# STM32C011D6Y6 register map
File version: 1.0
STM32C011D6Y6,STM32C011F4P6,STM32C011F4U6,STM32C011F6P6,STM32C011F6U6,STM32C011J4M6,STM32C011J6M6,STM32C031C4T6,STM32C031C4U6,STM32C031C6T6,STM32C031C6U6,STM32C031F4P6,STM32C031F6P6,STM32C031G4U6,STM32C031G6U6,STM32C031K4T6,STM32C031K4U6,STM32C031K6T6,STM32C031K6U6
Registers are 32-bit, access not given, reset 0x0 unless marked. A register's access mark holds for its fields unless they carry their own. Offsets are from the block's base; lines under a group give offsets from that group; [hi:lo] are bit positions; {n}, {i} and the like mark numbered series; 'fields as' and 'values as' point back to an identical list; <NAME> marks a mode.

## Memory map
0x40000400 TIM3
0x40002000 TIM14
0x40002800 RTC
0x40002C00 WWDG
0x40003000 IWDG
0x40004400 USART2
0x40005400 I2C1
0x40007000 PWR
0x40010000 SYSCFG
0x40010080 ITLINE
0x40012400 ADC
0x40012C00 TIM1
0x40013000 SPI1
0x40013800 USART1
0x40014400 TIM16
0x40014800 TIM17
0x40015800 DBG
0x40020000 DMA1
0x40020800 DMAMUX
0x40021000 RCC
0x40021800 EXTI
0x40022000 FLASH
0x40023000 CRC
0x50000000 GPIOA
0x50000400 GPIOB
0x50000800 GPIOC
0x50000C00 GPIOD
0x50001400 GPIOF

## TIM3
Base 0x40000400
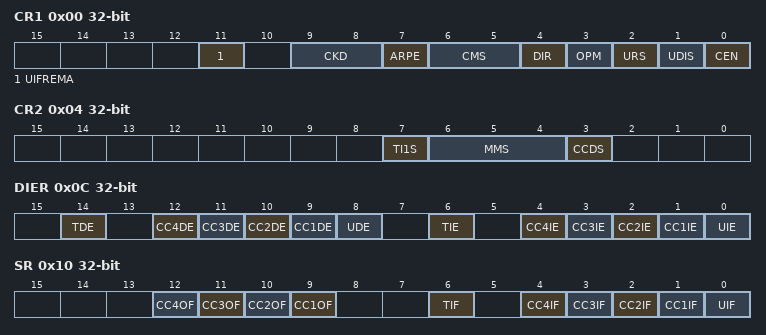
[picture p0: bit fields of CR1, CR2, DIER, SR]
0x00 CR1
  [11] UIFREMA, [9:8] CKD, [7] ARPE, [6:5] CMS, [4] DIR, [3] OPM, [2] URS, [1] UDIS, [0] CEN
0x04 CR2
  [7] TI1S, [6:4] MMS, [3] CCDS
0x08 SMCR
  [15] ETP, [14] ECE, [13:12] ETPS, [11:8] ETF, [7] MSM, [21:4] TS, [16:0] SMS
0x0C DIER
  [14] TDE, [n+8] CC{n}DE (n=1..4), [8] UDE, [6] TIE, [n] CC{n}IE (n=1..4), [0] UIE
0x10 SR
  [n+8] CC{n}OF (n=1..4), [6] TIF, [n] CC{n}IF (n=1..4), [0] UIF
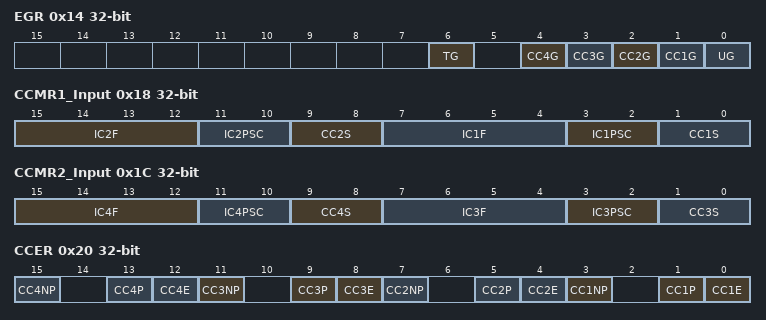
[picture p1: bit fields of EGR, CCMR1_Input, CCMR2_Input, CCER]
0x14 EGR
  [6] TG, [n] CC{n}G (n=1..4), [0] UG
0x18 CCMR1_Output
  [15] OC2CE, [24:12] OC2M, [11] OC2PE, [10] OC2FE, [9:8] CC2S, [7] OC1CE, [16:4] OC1M, [3] OC1PE, [2] OC1FE, [1:0] CC1S
0x18 CCMR1_Input
  [15:12] IC2F, [11:10] IC2PSC, [9:8] CC2S, [7:4] IC1F, [3:2] IC1PSC, [1:0] CC1S
0x1C CCMR2_Output
  [15] O24CE, [24:12] OC4M, [11] OC4PE, [10] OC4FE, [9:8] CC4S, [7] OC3CE, [16:4] OC3M, [3] OC3PE, [2] OC3FE, [1:0] CC3S
0x1C CCMR2_Input
  [15:12] IC4F, [11:10] IC4PSC, [9:8] CC4S, [7:4] IC3F, [3:2] IC3PSC, [1:0] CC3S
0x20 CCER
  [4n-1] CC{n}NP (n=1..4), [4n-3] CC{n}P (n=1..4), [4n-4] CC{n}E (n=1..4)
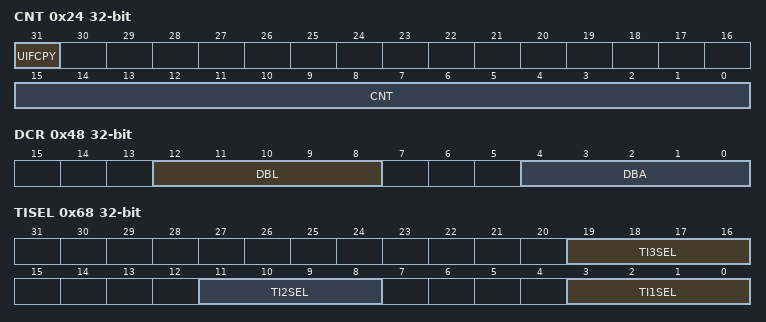
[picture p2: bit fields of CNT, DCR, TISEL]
0x24 CNT
  [31] UIFCPY, [15:0] CNT
0x28 PSC
  [15:0] PSC
0x2C ARR
  [15:0] ARR
{0x30+4i} CCR{i} (i=1..4)
  [15:0] CCR{i}
0x48 DCR
  [12:8] DBL, [4:0] DBA
0x4C DMAR
  [15:0] DMAB
0x60 AF1
  [17:14] ETRSEL
0x68 TISEL
  [19:16] TI3SEL, [11:8] TI2SEL, [3:0] TI1SEL

## TIM14
Base 0x40002000
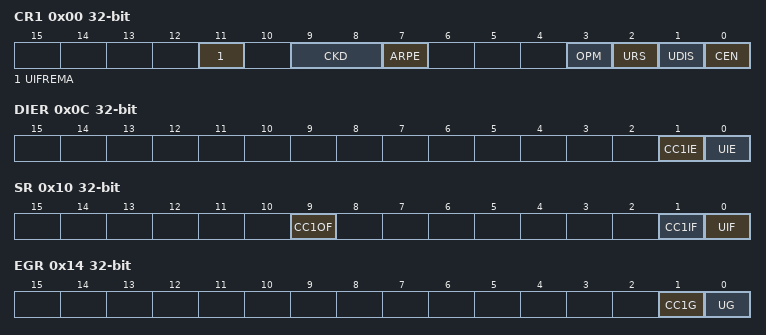
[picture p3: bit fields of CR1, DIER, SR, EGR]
0x00 CR1
  [11] UIFREMA, [9:8] CKD, [7] ARPE, [3] OPM, [2] URS, [1] UDIS, [0] CEN
0x0C DIER
  [1] CC1IE, [0] UIE
0x10 SR
  [9] CC1OF, [1] CC1IF, [0] UIF
0x14 EGR
  [1] CC1G, [0] UG
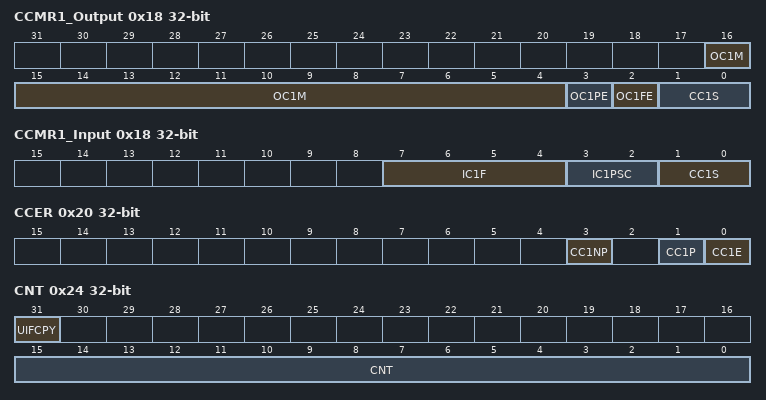
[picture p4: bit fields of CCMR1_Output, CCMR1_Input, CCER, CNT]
0x18 CCMR1_Output
  [16:4] OC1M, [3] OC1PE, [2] OC1FE, [1:0] CC1S
0x18 CCMR1_Input
  [7:4] IC1F, [3:2] IC1PSC, [1:0] CC1S
0x20 CCER
  [3] CC1NP, [1] CC1P, [0] CC1E
0x24 CNT
  [31] UIFCPY, [15:0] CNT
0x28 PSC
  [15:0] PSC
0x2C ARR
  [15:0] ARR
0x34 CCR1
  [15:0] CCR1
0x68 TISEL
  [3:0] TI1SEL

## RTC
Base 0x40002800
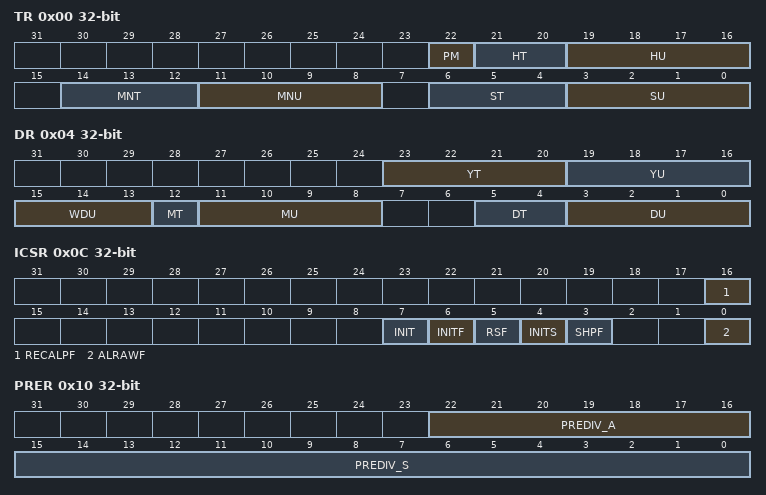
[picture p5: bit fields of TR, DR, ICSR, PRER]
0x00 TR
  [22] PM, [21:20] HT, [19:16] HU, [14:12] MNT, [11:8] MNU, [6:4] ST, [3:0] SU
0x04 DR
  [23:20] YT, [19:16] YU, [15:13] WDU, [12] MT, [11:8] MU, [5:4] DT, [3:0] DU
0x08 SSR
  [15:0] SS
0x0C ICSR
  [16] RECALPF, [7] INIT, [6] INITF, [5] RSF, [4] INITS, [3] SHPF, [0] ALRAWF
0x10 PRER
  [22:16] PREDIV_A, [15:0] PREDIV_S
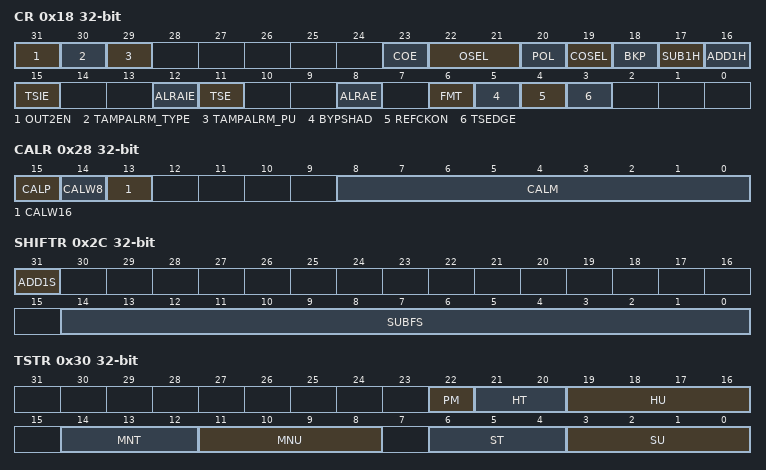
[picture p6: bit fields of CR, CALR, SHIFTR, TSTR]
0x18 CR
  [31] OUT2EN, [30] TAMPALRM_TYPE, [29] TAMPALRM_PU, [23] COE, [22:21] OSEL, [20] POL, [19] COSEL, [18] BKP, [17] SUB1H, [16] ADD1H, [15] TSIE, [12] ALRAIE, [11] TSE, [8] ALRAE, [6] FMT, [5] BYPSHAD, [4] REFCKON, [3] TSEDGE
0x24 WPR
  [7:0] KEY
0x28 CALR
  [15] CALP, [14] CALW8, [13] CALW16, [8:0] CALM
0x2C SHIFTR
  [31] ADD1S, [14:0] SUBFS
0x30 TSTR
  fields as TR
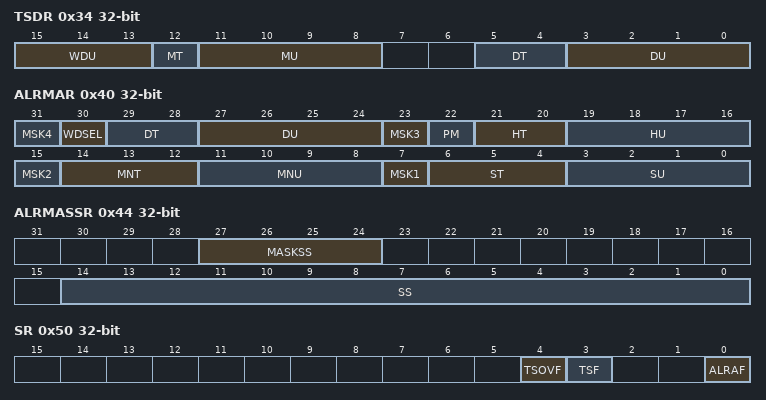
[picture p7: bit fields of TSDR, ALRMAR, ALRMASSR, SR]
0x34 TSDR
  [15:13] WDU, [12] MT, [11:8] MU, [5:4] DT, [3:0] DU
0x38 TSSSR
  [15:0] SS
0x40 ALRMAR
  [8n-1] MSK{n} (n=1..4), [30] WDSEL, [29:28] DT, [27:24] DU, [22] PM, [21:20] HT, [19:16] HU, [14:12] MNT, [11:8] MNU, [6:4] ST, [3:0] SU
0x44 ALRMASSR
  [27:24] MASKSS, [14:0] SS
0x50 SR
  [4] TSOVF, [3] TSF, [0] ALRAF
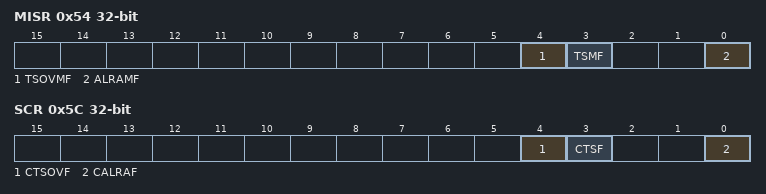
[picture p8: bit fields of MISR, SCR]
0x54 MISR
  [4] TSOVMF, [3] TSMF, [0] ALRAMF
0x5C SCR
  [4] CTSOVF, [3] CTSF, [0] CALRAF
